# GD32F5HC register map
File version: 1.0
CPU: CM33 r0p4, little endian, MPU, FPU, 4 interrupt priority bits
Registers are 32-bit, read-write, reset 0x0 unless marked. A register's access mark holds for its fields unless they carry their own. Offsets are from the block's base; [hi:lo] are bit positions; {n}, {i} and the like mark numbered series; 'fields as' and 'values as' point back to an identical list.

## CTC — Clock trim controller
Base 0x40006C00
Same registers: SEC_CTC 0x50006C00
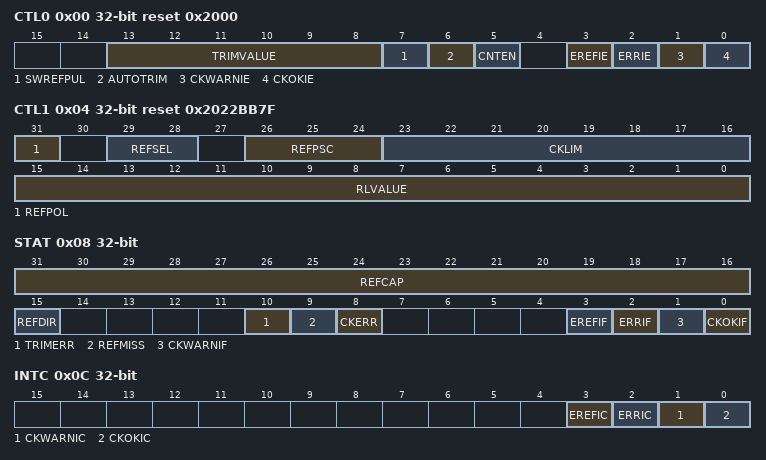
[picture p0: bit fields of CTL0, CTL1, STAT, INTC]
0x00 CTL0 access per field reset 0x2000 — Control register 0
  [13:8] TRIMVALUE rw — IRC48M trim value
  [7] SWREFPUL wo — Software reference source sync pulse
  [6] AUTOTRIM rw — Hardware automatically trim mode
  [5] CNTEN rw — CTC counter enable
  [3] EREFIE rw — EREFIF interrupt enable
  [2] ERRIE rw — Error (ERRIF) interrupt enable
  [1] CKWARNIE rw — Clock trim warning (CKWARNIF) interrupt enable
  [0] CKOKIE rw — Clock trim OK (CKOKIF) interrupt enable
0x04 CTL1 reset 0x2022BB7F — Control register 1
  [31] REFPOL — Reference signal source polarity
  [29:28] REFSEL — Reference signal source selection
  [26:24] REFPSC — Reference signal source prescaler
  [23:16] CKLIM — Clock trim base limit value
  [15:0] RLVALUE — CTC counter reload value
0x08 STAT ro — Status register
  [31:16] REFCAP — CTC counter capture when reference sync pulse.
  [15] REFDIR — CTC trim counter direction when reference sync pulse
  [10] TRIMERR — Trim value error bit
  [9] REFMISS — Reference sync pulse miss
  [8] CKERR — Clock trim error bit
  [3] EREFIF — Expect reference interrupt flag
  [2] ERRIF — Error interrupt flag
  [1] CKWARNIF — Clock trim warning interrupt flag
  [0] CKOKIF — Clock trim OK interrupt flag
0x0C INTC wo — Interrupt clear register
  [3] EREFIC — EREFIF interrupt clear bit
  [2] ERRIC — ERRIF interrupt clear bit
  [1] CKWARNIC — CKWARNIF interrupt clear bit
  [0] CKOKIC — CKOKIF interrupt clear bit

## EXTI — External interrupt/event controller
Base 0x40013C00
Same registers: SEC_EXTI 0x50013C00
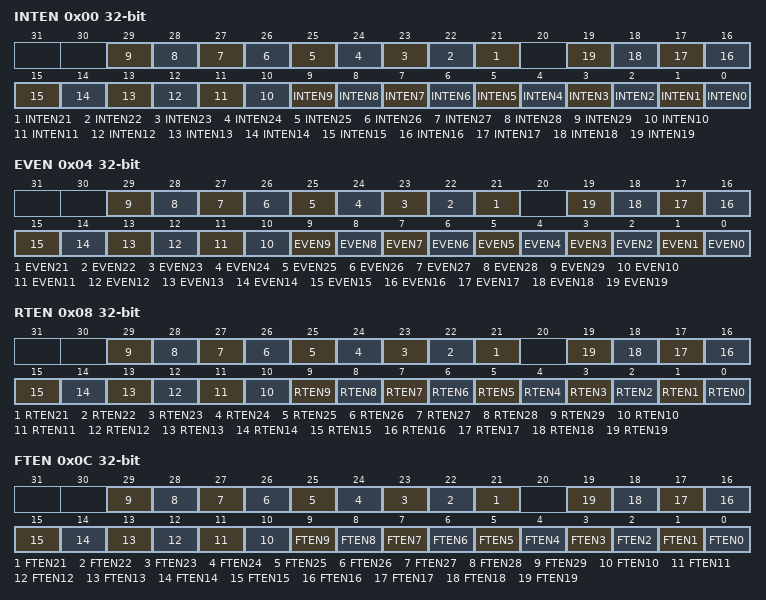
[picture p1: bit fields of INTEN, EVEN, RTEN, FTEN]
0x00 INTEN — Interrupt enable register (EXTI_INTEN)
  [n] INTEN{n} (n=21..29) — Enable Interrupt on line {n}
  [n] INTEN{n} (n=0..19) — Enable Interrupt on line {n}
0x04 EVEN — Event enable register (EXTI_EVEN)
  [n] EVEN{n} (n=21..29) — Enable Event on line {n}
  [n] EVEN{n} (n=0..19) — Enable Event on line {n}
0x08 RTEN — Rising Edge Trigger Enable register (EXTI_RTEN)
  [n] RTEN{n} (n=21..29) — Rising edge trigger enable of line {n}
  [n] RTEN{n} (n=0..19) — Rising edge trigger enable of line {n}
0x0C FTEN — Falling Egde Trigger Enable register (EXTI_FTEN)
  [n] FTEN{n} (n=21..29) — Falling edge trigger enable of line {n}
  [n] FTEN{n} (n=0..19) — Falling edge trigger enable of line {n}
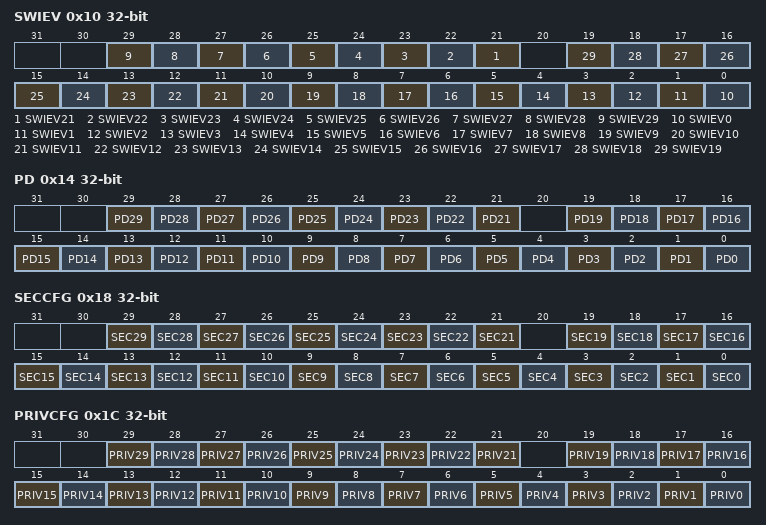
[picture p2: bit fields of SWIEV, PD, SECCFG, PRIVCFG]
0x10 SWIEV — Software interrupt event register (EXTI_SWIEV)
  [n] SWIEV{n} (n=21..29) — Interrupt/Event software trigger on line {n}
  [n] SWIEV{n} (n=0..19) — Interrupt/Event software trigger on line {n}
0x14 PD — Pending register (EXTI_PD)
  [n] PD{n} (n=21..29) — Interrupt pending status of line {n}
  [n] PD{n} (n=0..19) — Interrupt pending status of line {n}
0x18 SECCFG — EXTI security configuration register
  [n] SEC{n} (n=21..29) — Security enable on event input {n}
  [n] SEC{n} (n=0..19) — Security enable on event input {n}
0x1C PRIVCFG — EXTI privilege configuration register
  [n] PRIV{n} (n=21..29) — Security enable on event input {n}
  [n] PRIV{n} (n=0..19) — Security enable on event input {n}
0x20 LOCK — EXTI lock register
  [0] LOCK — Global security and privilege configuration registers

## FS_HOST — USB on the go full speed host
Base 0x49000400
Same registers: SEC_FS_HOST 0x59000400
0x00 HCTL — host configuration register (HCTL)
  [1:0] CLKSEL — clock select for USB clock
0x04 HFT reset 0xBB80 — Host frame interval register
  [15:0] FRI — Frame interval
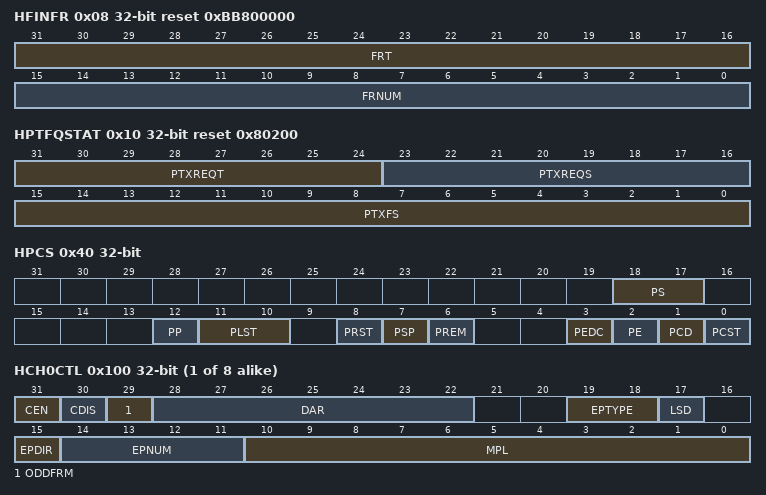
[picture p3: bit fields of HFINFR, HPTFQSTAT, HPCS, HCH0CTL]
0x08 HFINFR ro reset 0xBB800000 — OTG_FS host frame number/frame time remaining register (HFINFR)
  [31:16] FRT — Frame remaining time
  [15:0] FRNUM — Frame number
0x10 HPTFQSTAT ro reset 0x80200 — Host periodic transmit FIFO/queue status register (HPTFQSTAT)
  [31:24] PTXREQT — Top of the periodic transmit request queue
  [23:16] PTXREQS — Periodic transmit request queue space available
  [15:0] PTXFS — Periodic transmit data FIFO space available
0x14 HACHINT ro — Host all channels interrupt register
  [7:0] HACHINT — Host all channel interrupts
0x18 HACHINTEN — host all channels interrupt mask register
  [7:0] CINTEN — Channel interrupt enable
0x40 HPCS access per field — Host port control and status register (USBFS_HPCS)
  [18:17] PS ro — Port speed
  [12] PP rw — Port power
  [11:10] PLST ro — Port line status
  [8] PRST rw — Port reset
  [7] PSP rw — Port suspend
  [6] PREM rw — Port resume
  [3] PEDC rw — Port enable/disable change
  [2] PE rw — Port enable
  [1] PCD rw — Port connect detected
  [0] PCST ro — Port connect status
{0x100+0x20*i} HCH{i}CTL (i=0..7) — host channel-{i} characteristics register (HCH{i}CTL)
  [31] CEN — Channel enable
  [30] CDIS — Channel disable
  [29] ODDFRM — Odd frame
  [28:22] DAR — Device address
  [19:18] EPTYPE — Endpoint type
  [17] LSD — Low-speed device
  [15] EPDIR — Endpoint direction
  [14:11] EPNUM — Endpoint number
  [10:0] MPL — Maximum packet size
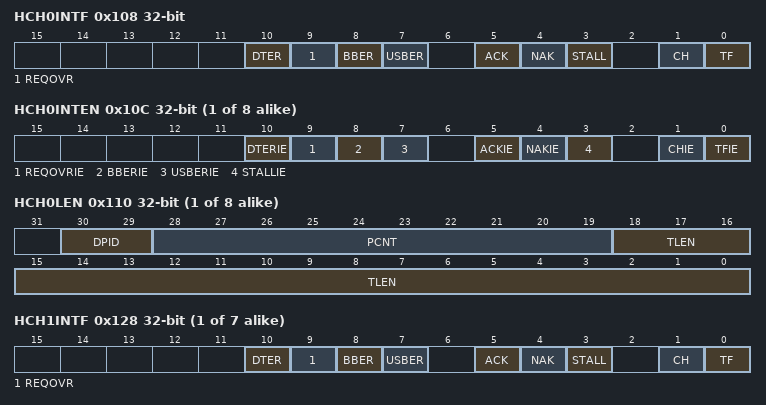
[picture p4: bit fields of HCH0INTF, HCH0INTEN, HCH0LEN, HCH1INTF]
0x108 HCH0INTF — host channel-0 interrupt register (USBFS_HCHxINTF)
  [10] DTER — Data toggle error
  [9] REQOVR — Request queue overrun
  [8] BBER — Babble error
  [7] USBER — USB bus error
  [5] ACK — ACK response received/transmitted interrupt
  [4] NAK — NAK response received interrupt
  [3] STALL — STALL response received interrupt
  [1] CH — Channel halted
  [0] TF — Transfer finished
{0x10C+0x20*i} HCH{i}INTEN (i=0..7) — host channel-{i} interrupt enable register (HCH{i}INTEN)
  [10] DTERIE — Data toggle error interrupt enable
  [9] REQOVRIE — request queue overrun interrupt enable
  [8] BBERIE — Babble error interrupt enable
  [7] USBERIE — USB bus error interrupt enable
  [5] ACKIE — ACK interrupt enable
  [4] NAKIE — NAK interrupt enable
  [3] STALLIE — STALL interrupt enable
  [1] CHIE — Channel halted interrupt enable
  [0] TFIE — Transfer completed interrupt enable
{0x110+0x20*i} HCH{i}LEN (i=0..7) — host channel-{i} transfer length register
  [30:29] DPID — Data PID
  [28:19] PCNT — Packet count
  [18:0] TLEN — Transfer length
{0x108+0x20*i} HCH{i}INTF (i=1..7) — host channel-{i} interrupt register (HCH{i}INTF)
  fields as HCH0INTF
